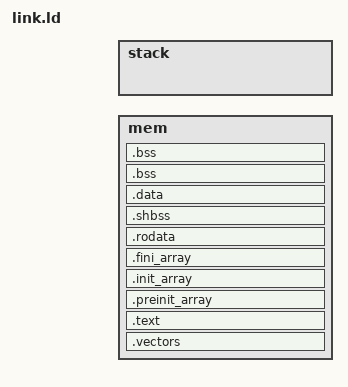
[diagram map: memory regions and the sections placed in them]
SEARCH_DIR(.)
__DYNAMIC  =  0;

MEMORY
{
    mem   : ORIGIN = MEM_ORIGIN, LENGTH = MEM_LENGTH
    stack : ORIGIN = STACK_ORIGIN, LENGTH = STACK_LENGTH
}

/* Stack information variables */
_stack_len     = LENGTH(stack);
_stack_end     = ORIGIN(stack);
_stack_start   = ORIGIN(stack) + LENGTH(stack);
__global_pointer$ = 0; /* 2K */

/* We have to align each sector to word boundaries as our current s19->slm
 * conversion scripts are not able to handle non-word aligned sections. */

SECTIONS
{
    .vectors :
    {
        . = ALIGN(4);
        KEEP(*(.vectors))
    } > mem

    .text : {
        . = ALIGN(4);
        _stext = .;
        *(.text)
        _etext  =  .;
        __CTOR_LIST__ = .;
        LONG((__CTOR_END__ - __CTOR_LIST__) / 4 - 2)
        *(.ctors)
        LONG(0)
        __CTOR_END__ = .;
        __DTOR_LIST__ = .;
        LONG((__DTOR_END__ - __DTOR_LIST__) / 4 - 2)
        *(.dtors)
        LONG(0)
        __DTOR_END__ = .;
        *(.lit)
        *(.shdata)
        _endtext = .;
    }  > mem

    /*--------------------------------------------------------------------*/
    /* Global constructor/destructor segement                             */
    /*--------------------------------------------------------------------*/

    .preinit_array     :
    {
      PROVIDE_HIDDEN (__preinit_array_start = .);
      KEEP (*(.preinit_array))
      PROVIDE_HIDDEN (__preinit_array_end = .);
    } > mem

    .init_array     :
    {
      PROVIDE_HIDDEN (__init_array_start = .);
      KEEP (*(SORT(.init_array.*)))
      KEEP (*(.init_array ))
      PROVIDE_HIDDEN (__init_array_end = .);
    } > mem

    .fini_array     :
    {
      PROVIDE_HIDDEN (__fini_array_start = .);
      KEEP (*(SORT(.fini_array.*)))
      KEEP (*(.fini_array ))
      PROVIDE_HIDDEN (__fini_array_end = .);
    } > mem

    .rodata : {
        . = ALIGN(4);
        *(.rodata);
        *(.rodata.*)
    } > mem

    .shbss :
    {
        . = ALIGN(4);
        *(.shbss)
    } > mem

    .data : {
        . = ALIGN(4);
        sdata  =  .;
        _sdata  =  .;
        *(.data);
        *(.data.*)
        edata  =  .;
        _edata  =  .;
    } > mem

    .bss :
    {
        . = ALIGN(4);
        _bss_start = .;
        *(.bss)
        *(.bss.*)
        *(.sbss)
        *(.sbss.*)
        *(COMMON)
        _bss_end = .;
    } > mem

    .stab  0 (NOLOAD) :
    {
        [ .stab ]
    }

    .stabstr  0 (NOLOAD) :
    {
        [ .stabstr ]
    }

    .bss :
    {
        . = ALIGN(4);
        _end = .;
    } > mem
}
